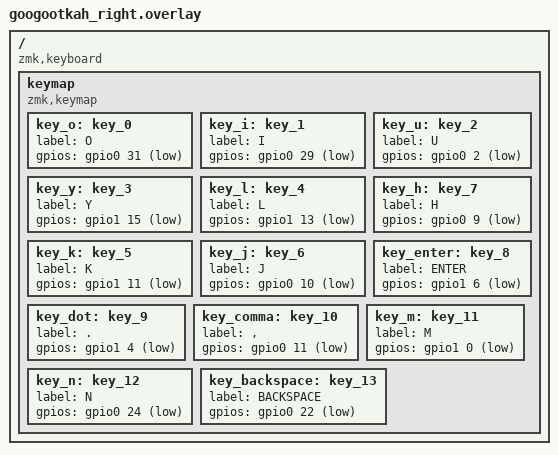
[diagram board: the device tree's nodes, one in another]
/ {
    compatible = "zmk,keyboard";

    keymap {
        compatible = "zmk,keymap";

        // Red 1
        key_o: key_0 { label = "O"; gpios = <&gpio0 31 GPIO_ACTIVE_LOW>; };
        key_i: key_1 { label = "I"; gpios = <&gpio0 29 GPIO_ACTIVE_LOW>; };
        key_u: key_2 { label = "U"; gpios = <&gpio0 2  GPIO_ACTIVE_LOW>; };
        key_y: key_3 { label = "Y"; gpios = <&gpio1 15 GPIO_ACTIVE_LOW>; };

        // Red 2
        key_l: key_4 { label = "L"; gpios = <&gpio1 13 GPIO_ACTIVE_LOW>; };
        key_k: key_5 { label = "K"; gpios = <&gpio1 11 GPIO_ACTIVE_LOW>; };
        key_j: key_6 { label = "J"; gpios = <&gpio0 10 GPIO_ACTIVE_LOW>; };
        key_h: key_7 { label = "H"; gpios = <&gpio0 9  GPIO_ACTIVE_LOW>; };

        // Red 3
        key_enter: key_8 { label = "ENTER"; gpios = <&gpio1 6  GPIO_ACTIVE_LOW>; };
        key_dot: key_9   { label = "."; gpios = <&gpio1 4  GPIO_ACTIVE_LOW>; };
        key_comma: key_10 { label = ","; gpios = <&gpio0 11 GPIO_ACTIVE_LOW>; };
        key_m: key_11    { label = "M"; gpios = <&gpio1 0  GPIO_ACTIVE_LOW>; };
        key_n: key_12    { label = "N"; gpios = <&gpio0 24 GPIO_ACTIVE_LOW>; };
        key_backspace: key_13 { label = "BACKSPACE"; gpios = <&gpio0 22 GPIO_ACTIVE_LOW>; };
    };
};
